# wl_phy_ana_pg_secure register map
Vendor: Texas Instruments
Registers are 32-bit, access per field, reset 0x0 unless marked. A register's access mark holds for its fields unless they carry their own. Offsets are as the file gives them; [hi:lo] are bit positions.

## wl_phy_ana_pg_secure (part 3 of 3)
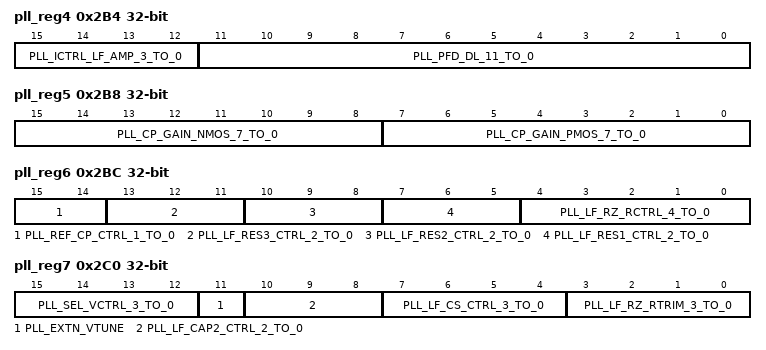
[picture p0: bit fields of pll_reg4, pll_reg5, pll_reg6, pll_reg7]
0x2B4 pll_reg4 — - not used - '0' SW PFD_RESET2; '1' synth_dig dual PFD reset - '0' SW PFD_RESET; '1' synth_dig PFD reset - '0' No UP Delay; '1' extra UP delay based on '00' one pres45 clk delay for UP; '01' - 1.5 pres45 clk delay for UP; '10' 2 pres45 clk delay for UP; '11' - 2.5 pres45 clk delay for UP; - '0' No DN Delay; '1' extra DN delay based on '00' one pres45 clk delay for DN; '01' - 1.5 pres45 clk delay for DN; '10' 2 pres45 clk delay for DN; '11' - 2.5 pres45 clk delay for DN;
  [15:12] PLL_ICTRL_LF_AMP_3_TO_0 rw — Current control for Loop Filter Amp '0000' - No Current '0001' - Max Current (6mA) '0100' - A band current (1.6mA) '0110' - BG band Current (1.2mA) '1111' - Min Current (500uA)
  [11:0] PLL_PFD_DL_11_TO_0 rw — - not used - '0' SW PFD_RESET2; '1' synth_dig dual PFD reset - '0' SW PFD_RESET; '1' synth_dig PFD reset - '0' No UP Delay; '1' extra UP delay based on '00' one pres45 clk delay for UP; '01' - 1.5 pres45 clk delay for UP; '10' 2 pres45 clk delay for UP; '11' - 2.5 pres45 clk delay for UP; - '0' No DN Delay; '1' extra DN delay based on '00' one pres45 clk delay for DN; '01' - 1.5 pres45 clk delay for DN; '10' 2 pres45 clk delay for DN; '11' - 2.5 pres45 clk delay for DN;
0x2B8 pll_reg5 — CP Gain for UP '0x00' - No Current '0x01' - 125uA 0x02 - 62uA 0x04 -125uA 0x08 - 250uA 0x10 - 500uA 0x20 - 1mA 0x40 - 2mA 0x80 - 2mA
  [15:8] PLL_CP_GAIN_NMOS_7_TO_0 rw — CP Gain for DN '0x00' - No Current '0x01' - 125uA 0x02 - 62uA 0x04 -125uA 0x08 - 250uA 0x10 - 500uA 0x20 - 1mA 0x40 - 2mA 0x80 - 2mA
  [7:0] PLL_CP_GAIN_PMOS_7_TO_0 rw — CP Gain for UP '0x00' - No Current '0x01' - 125uA 0x02 - 62uA 0x04 -125uA 0x08 - 250uA 0x10 - 500uA 0x20 - 1mA 0x40 - 2mA 0x80 - 2mA
0x2BC pll_reg6 — Res control for LF Rz 'XX000' 4.5K 'XX001' 5.5K 'XX010' 6.8K 'XX011' 8.8K '011XX' 3K '101XX' 1.5K '111XX' 800
  [15:14] PLL_REF_CP_CTRL_1_TO_0 rw — Res control for Loop filter positive node VCM '00' not connected '01' 6KOhm '10' 4KOhm '11' 6K||4KOhm = 2.4K
  [13:11] PLL_LF_RES3_CTRL_2_TO_0 rw — Res control for LF LPF3 '000' 5.5K '001' 5.5K||8K '010 5.5K || 16K '100' 5.5K|| 32K
  [10:8] PLL_LF_RES2_CTRL_2_TO_0 rw — Res control for LF LPF2 '000' 5.5K '001' 5.5K||8K '010 5.5K || 16K '100' 5.5K|| 32K
  [7:5] PLL_LF_RES1_CTRL_2_TO_0 rw — Res control for LF LPF1 '000' 3.5K '001' 3.5K||5K '010 3.5K || 10K '100' 3.5K|| 20K
  [4:0] PLL_LF_RZ_RCTRL_4_TO_0 rw — Res control for LF Rz 'XX000' 4.5K 'XX001' 5.5K 'XX010' 6.8K 'XX011' 8.8K '011XX' 3K '101XX' 1.5K '111XX' 800
0x2C0 pll_reg7 — RTRIM for RZ over PVT
  [15:12] PLL_SEL_VCTRL_3_TO_0 rw — Control to give VCTRL through R ladder '0000' - 240mV '0001' - 240mV +60mV '1000' - 240mV + 8*60mV '1111' - 1.14V
  [11] PLL_EXTN_VTUNE rw — Enable External Vtune R ladder
  [10:8] PLL_LF_CAP2_CTRL_2_TO_0 rw — Cap control for LF LPF2 '0' - 13pF; '1' - 13pF+6.5pF Cap control for LF LPF3 '0' - 15pF; '1' - 15pF+5.5pF Cap control for LF LPF1 '0' - 5pF; '1' - 5pF+9.5pF
  [7:4] PLL_LF_CS_CTRL_3_TO_0 rw — Cap control for LF CS - not used '000' - 1.5pF '001' -1.5pF + 1.75pF '010' - 1.5pF+3.5pF '100' 1.5pF+7pF
  [3:0] PLL_LF_RZ_RTRIM_3_TO_0 rw — RTRIM for RZ over PVT
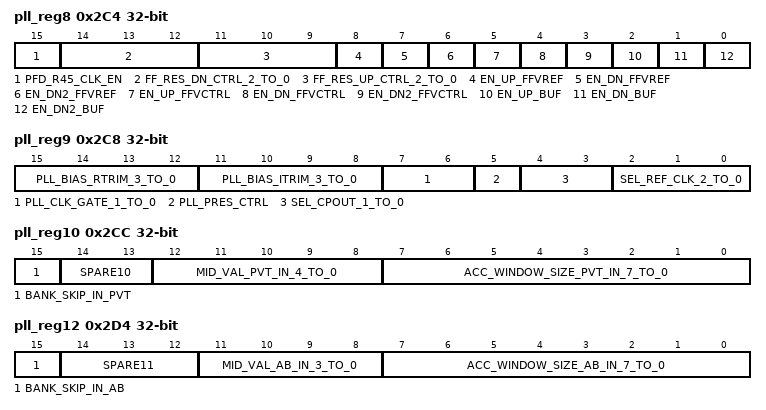
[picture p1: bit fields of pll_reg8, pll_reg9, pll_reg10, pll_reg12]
0x2C4 pll_reg8 — Enable DN2 buffer to FF
  [15] PFD_R45_CLK_EN rw — Enable Pres45 clk to PFD delay Gen block
  [14:12] FF_RES_DN_CTRL_2_TO_0 rw — Res control for FF DN path for both FFVCTRL FFVREF not used '00' - 4KOhm '01' 6KOhm '10' 8KOhm '11' 12KOhm
  [11:9] FF_RES_UP_CTRL_2_TO_0 rw — Res control for FF UP path for both FFVCTRL FFVREF not used '00' - 4KOhm '01' 6KOhm '10' 8KOhm '11' 12KOhm
  [8] EN_UP_FFVREF rw — Enable UP FF to VREF node
  [7] EN_DN_FFVREF rw — Enable DN FF to VREF node
  [6] EN_DN2_FFVREF rw — Enable DN2 FF to VREF node
  [5] EN_UP_FFVCTRL rw — Enable UP FF to VCTRL node
  [4] EN_DN_FFVCTRL rw — Enable DN FF to VCTRL node
  [3] EN_DN2_FFVCTRL rw — Enable DN2 FF to VCTRL node
  [2] EN_UP_BUF rw — Enable UP buffer to FF
  [1] EN_DN_BUF rw — Enable DN buffer to FF
  [0] EN_DN2_BUF rw — Enable DN2 buffer to FF
0x2C8 pll_reg9 — Mux select for DLL CLK to PLL Mux select for XTAL clk to PLL
  [15:12] PLL_BIAS_RTRIM_3_TO_0 rw — Res trim inside V2I amp for amp bias current
  [11:8] PLL_BIAS_ITRIM_3_TO_0 rw — Res trim for V2I Resistor for mirror currents
  [7:6] PLL_CLK_GATE_1_TO_0 rw — Enable DLL CLK out to synth_dig Enable Prescaler clk out to synth_dig
  [5] PLL_PRES_CTRL rw — Control for dummy logic to be kept 0
  [4:3] SEL_CPOUT_1_TO_0 rw — Mux select for DLL VCTRL and PLL VCTRL to test mode '01' - PLL VCTRL to test mode '10' - DLL VCTRL to test mode
  [2:0] SEL_REF_CLK_2_TO_0 rw — Mux select for DLL CLK to PLL Mux select for XTAL clk to PLL
0x2CC pll_reg10 — Number of FREFs over which the FCW should be integrated for error computation for PVT tuning
  [15] BANK_SKIP_IN_PVT rw — Set this bit to skip PVT bank during tuning. The Mid value configured will apply as the PVT Code
  [14:13] SPARE10 rw — SPARE
  [12:8] MID_VAL_PVT_IN_4_TO_0 rw — PVT Mid value. This is the value at which the synth will start for PVT code for convergence
  [7:0] ACC_WINDOW_SIZE_PVT_IN_7_TO_0 rw — Number of FREFs over which the FCW should be integrated for error computation for PVT tuning
0x2D0 pll_reg11 — Beta value for PVT Bank Tuning
  [15:0] BETA_PVT_IN_15_TO_0 rw
0x2D4 pll_reg12 — Number of FREFs over which the FCW should be integrated for error computation for AB tuning
  [15] BANK_SKIP_IN_AB rw — Set this bit to skip AB bank during tuning. The Mid value configured will apply as the AB Code
  [14:12] SPARE11 rw — SPARE
  [11:8] MID_VAL_AB_IN_3_TO_0 rw — AB Mid value. This is the value at which the synth will start for AB code for convergence
  [7:0] ACC_WINDOW_SIZE_AB_IN_7_TO_0 rw — Number of FREFs over which the FCW should be integrated for error computation for AB tuning
0x2D8 pll_reg13 — Beta value for AB Bank Tuning
  [15:0] BETA_AB_IN_15_TO_0 rw
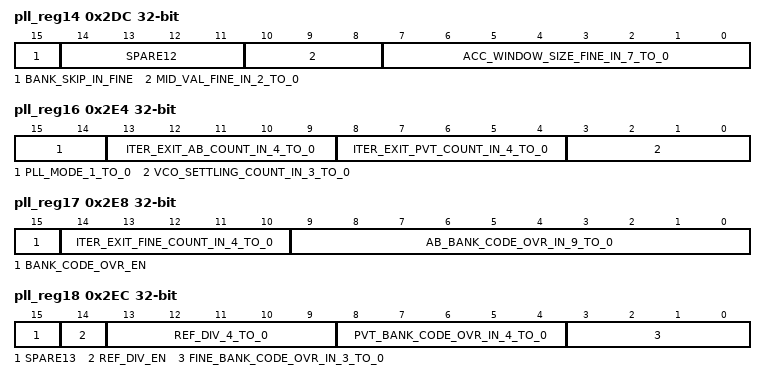
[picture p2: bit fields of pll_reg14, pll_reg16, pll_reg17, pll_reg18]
0x2DC pll_reg14 — Number of FREFs over which the FCW should be integrated for error computation for FINE tuning
  [15] BANK_SKIP_IN_FINE rw — Set this bit to skip FINE bank during tuning. The Mid value configured will apply as the FINE Code
  [14:11] SPARE12 rw — SPARE
  [10:8] MID_VAL_FINE_IN_2_TO_0 rw — FINE Mid value. This is the value at which the synth will start for FINE code for convergence
  [7:0] ACC_WINDOW_SIZE_FINE_IN_7_TO_0 rw — Number of FREFs over which the FCW should be integrated for error computation for FINE tuning
0x2E0 pll_reg15 — Beta value for FINE Bank Tuning
  [15:0] BETA_FINE_IN_15_TO_0 rw
0x2E4 pll_reg16 — Number of FREF clocks to wait for VCO to settle after every bank code update till error accumulation count starts
  [15:14] PLL_MODE_1_TO_0 rw — Defines if the PLL should work in Auto Mode or Stepping Mode 00_ Full auto mode for Bank switching as well as on every iteration within the bank tuning 01_ Iteration stepping is auto_ but Bank switching is Manual. After every bank tuning_ interrupt is generated and tuning is paused. Next bank tuning resumes on synth_kickoff retrigger 10_ Bank switching is auto_ but Iteration stepping is Manual. After every iteration_ interrupt is generated and tuning is paused and resumes on iteration_single_step_in trigger 11_ Both Bank switching and Iteration stepping are manual. Interrupt is generated on every iteration step as well as bank switch and resume on iteration_single_step_in and synth_kickoff triggers respectively
  [13:9] ITER_EXIT_AB_COUNT_IN_4_TO_0 rw — Number of counts after which the iterations for AB bank should stop and signal end of tuning for AB bank for bank switching to FINE
  [8:4] ITER_EXIT_PVT_COUNT_IN_4_TO_0 rw — Number of counts after which the iterations for PVT bank should stop and signal end of tuning for PVT bank for bank switching to AB
  [3:0] VCO_SETTLING_COUNT_IN_3_TO_0 rw — Number of FREF clocks to wait for VCO to settle after every bank code update till error accumulation count starts
0x2E8 pll_reg17 — Override value for the AB Bank code to be used if bank_code_ovr_en is set
  [15] BANK_CODE_OVR_EN rw — Override computed bank code values Set this bit to use override bank code values instead of what is computed every iteration. Can be used for debug mode or FW workarounds
  [14:10] ITER_EXIT_FINE_COUNT_IN_4_TO_0 rw — Number of counts after which the iterations for FINE bank should stop and signal end of tuning for FINE bank for signalling end of tune indication
  [9:0] AB_BANK_CODE_OVR_IN_9_TO_0 rw — Override value for the AB Bank code to be used if bank_code_ovr_en is set
0x2EC pll_reg18 — Override value for the FINE Bank code to be used if bank_code_ovr_en is set
  [15] SPARE13 rw — SPARE
  [14] REF_DIV_EN rw — Enable REF CLK division for FLL counter_ internal FSM works on REF CLK
  [13:9] REF_DIV_4_TO_0 rw — REF CLK division factor for FLL
  [8:4] PVT_BANK_CODE_OVR_IN_4_TO_0 rw — Override value for the PVT Bank code to be used if bank_code_ovr_en is set
  [3:0] FINE_BANK_CODE_OVR_IN_3_TO_0 rw — Override value for the FINE Bank code to be used if bank_code_ovr_en is set
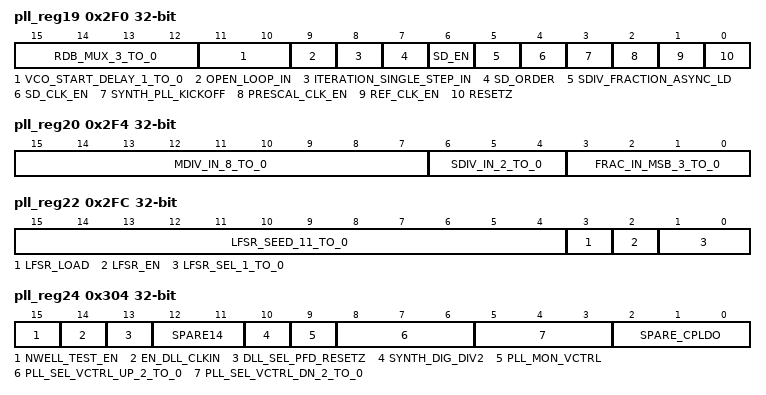
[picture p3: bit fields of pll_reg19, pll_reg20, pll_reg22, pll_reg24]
0x2F0 pll_reg19 — RESETZ
  [15:12] RDB_MUX_3_TO_0 rw — rdb_mux Read back controls 0x6 = PLLOUT_REG2 = fcw_counter_expected 0x5 = PLLOUT_REG2 = fcw_counter 0x4 = PLLOUT_REG2 = fcw_error 0x3 = PLLOUT_REG2 = fcw_error_acc 0x2 = PLLOUT_REG2 = beta_scale_selected_val 0x1 = PLLOUT_REG2 = bank_code_err; bank_code_iter_final 0x0 = PLLOUT_REG2 = fine_bank_code_apply ab_bank_code_apply
  [11:10] VCO_START_DELAY_1_TO_0 rw — controls the delay between _synth_pll_kickoff_ and delayed pll_kickoff(when the mid coded gets apllied to the VCO) 00 _64 clock cycles of ref_clk 01_128 clock cycles of ref_clk 10_16 clock cycles of ref_clk 11 _32 clock cycles of ref_clk
  [9] OPEN_LOOP_IN rw — Not used
  [8] ITERATION_SINGLE_STEP_IN rw
  [7] SD_ORDER rw
  [6] SD_EN rw — Enable SDM
  [5] SDIV_FRACTION_ASYNC_LD rw — A toggle of this signal loads new SDIV and Fraction after digital tune_ must be stable at least two sdm clock cycles. Added for Osprey support of PLL Reloc
  [4] SD_CLK_EN rw — Enable SDM CLK
  [3] SYNTH_PLL_KICKOFF rw — Enable Digital VCO cap tuning
  [2] PRESCAL_CLK_EN rw — Enable Prescaler CLK
  [1] REF_CLK_EN rw — Enable Reference CLK
  [0] RESETZ rw
0x2F4 pll_reg20 — MSB part of fractional input
  [15:7] MDIV_IN_8_TO_0 rw — Current mdiv_in allocation of 9 bits
  [6:4] SDIV_IN_2_TO_0 rw — Current sdiv_in allocation of 3 bits
  [3:0] FRAC_IN_MSB_3_TO_0 rw — MSB part of fractional input
0x2F8 pll_reg21 — LSB part of fractional input
  [15:0] FRAC_IN_LSB_15_TO_0 rw
0x2FC pll_reg22
  [15:4] LFSR_SEED_11_TO_0 rw — seed value for lfsr to dither the LSB
  [3] LFSR_LOAD rw — Load the lfsr seed to Lfsr register
  [2] LFSR_EN rw — enable lfsr to dither frac LSB
  [1:0] LFSR_SEL_1_TO_0 rw — 00 _ [15] ^[14] ^[12]^[3] 01 _ [15]^[12]^[8]^[5] 10 _[15]^[14]^[13]^[12]^[11]^[0] 11 _ [15]
0x300 pll_reg23 — acc1 seed value to be loaded initially default is 0
  [15:0] SDM_ACC1_SEED_15_TO_0 rw
0x304 pll_reg24 — Spare
  [15] NWELL_TEST_EN rw — Enable NWELL testmode
  [14] EN_DLL_CLKIN rw — Enable input clock to DLL
  [13] DLL_SEL_PFD_RESETZ rw — Mux Select for DLL RESETZ in DLL PFD
  [12:11] SPARE14 rw — SPARE
  [10] SYNTH_DIG_DIV2 rw — Enable DIV2 for Pres clk to synth dig
  [9] PLL_MON_VCTRL rw — Enable Monitoring of VCTRL to detect PLL out of lock
  [8:6] PLL_SEL_VCTRL_UP_2_TO_0 rw — Select high voltage limit for VCTRL to detect PLL out of lock '111' - 1.23V every step is 70mV decrease
  [5:3] PLL_SEL_VCTRL_DN_2_TO_0 rw — Select low voltage limit for VCTRL to detect PLL out of lock '000' - 185mV every step is 70mV increase
  [2:0] SPARE_CPLDO rw — Spare
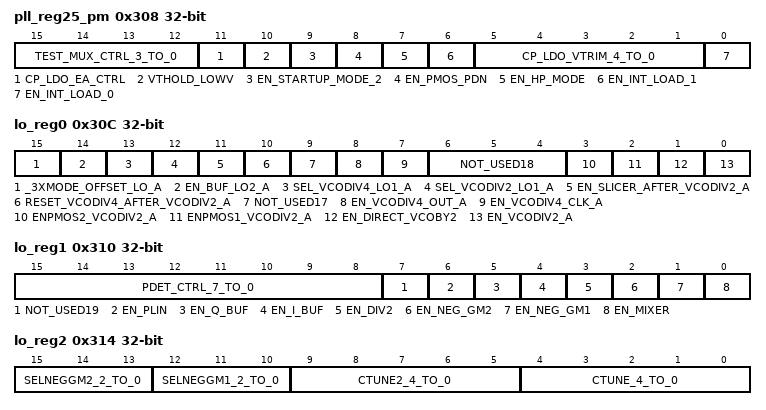
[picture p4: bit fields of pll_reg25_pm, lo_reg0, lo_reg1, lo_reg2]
0x308 pll_reg25_pm — EN_INTLOAD Enable internal load. Making any bit ?H? enables 50% of the internal load ?L_L? = 0mA ?L_H? = 3.5mA (across PVT_ 1.4mA ? 6mA) ?H_L? = 3.5mA (across PVT_ 1.4mA ? 6mA) ?H_H? = 7mA (across PVT_ 2.8mA ? 11mA)
  [15:12] TEST_MUX_CTRL_3_TO_0 rw — TEST MUX Control 'H' bring out Vout_2 'H' Enable Tmux
  [11] CP_LDO_EA_CTRL rw — Used in EA block?s start-up amp ?L? = Short out 20k degen of current source which pumps current into EA cap ?H? = Enable the 20k degen of current source which pumps current into EA cap
  [10] VTHOLD_LOWV rw — Start-up bit for CPLDO. Enables extra current through EA ?H? = disable extra current(slow start)_ ?L? = fast-start
  [9] EN_STARTUP_MODE_2 rw — EN_STARTUPMODE_2 Enable fast start mode 2 (This is a static bit_ It doesn?t need to toggle) ?H? = burn 10uA extra current in error amp ?L? = burn only 2.5uA extra current in error amp
  [8] EN_PMOS_PDN rw — EN_PMOSPDN Enable pull down path in buffer to reduce overshoots in Vout ?L? = Enable PD_ ?H? = Disable PD
  [7] EN_HP_MODE rw — EN_HPMODE Enable High Power mode_ i.e. _ burn extra tail current in buffer ?H? = Enable HPmode_ ?L?= Disable Hpmode
  [6] EN_INT_LOAD_1 rw — EN_INTLOAD Enable internal load. Making any bit ?H? enables 50% of the internal load ?L_L? = 0mA ?L_H? = 3.5mA (across PVT_ 1.4mA ? 6mA) ?H_L? = 3.5mA (across PVT_ 1.4mA ? 6mA) ?H_H? = 7mA (across PVT_ 2.8mA ? 11mA)
  [5:1] CP_LDO_VTRIM_4_TO_0 rw — VOUT_TRIM LDO trim LSB approximately 20mV
  [0] EN_INT_LOAD_0 rw — EN_INTLOAD Enable internal load. Making any bit ?H? enables 50% of the internal load ?L_L? = 0mA ?L_H? = 3.5mA (across PVT_ 1.4mA ? 6mA) ?H_L? = 3.5mA (across PVT_ 1.4mA ? 6mA) ?H_H? = 7mA (across PVT_ 2.8mA ? 11mA)
0x30C lo_reg0 — Enable A band VCODIV2
  [15] _3XMODE_OFFSET_LO_A rw — Configures the A band output LO2 (2nd input to OFFSET LO MIXER) to high enabling 3x mode of OFFSET MIXER
  [14] EN_BUF_LO2_A rw — Enables buffer which sends VCO A band as LO2 input to OFFSET LO MIXER
  [13] SEL_VCODIV4_LO1_A rw — Selects VCO_4 signal as LO1 input to OFFSET LO MIXER
  [12] SEL_VCODIV2_LO1_A rw — Selects VCO_2 signal as LO1 input to OFFSET LO MIXER
  [11] EN_SLICER_AFTER_VCODIV2_A rw — Enable buffer after A band VCODIV2 module
  [10] RESET_VCODIV4_AFTER_VCODIV2_A rw — Reset IVCODIV4 after A band VCODIV2
  [9] NOT_USED17 rw — Not used
  [8] EN_VCODIV4_OUT_A rw — Enable output of VCODIV4 divider sitting after VCODIV2 divider in A band VCODIV block
  [7] EN_VCODIV4_CLK_A rw — Enable clock of VCODIV4 divider sitting after VCODIV2 divider in A band VCODIV block
  [6:4] NOT_USED18 rw — Not used
  [3] ENPMOS2_VCODIV2_A rw — Enable 2X extra drive for PMOS in A band VCODIV2
  [2] ENPMOS1_VCODIV2_A rw — Enable 1X extra drive for PMOS in A band VCODIV2
  [1] EN_DIRECT_VCOBY2 rw — Enable the path of VCO_2 muxed at final buffer of offset-LO drivers to enable 3x(VCO_2) mode
  [0] EN_VCODIV2_A rw — Enable A band VCODIV2
0x310 lo_reg1 — Enable of offset LO mixer
  [15:8] PDET_CTRL_7_TO_0 rw — PDET configuration
  [7] NOT_USED19 rw — Not used
  [6] EN_PLIN rw — Controls the step size of bias generation in div2
  [5] EN_Q_BUF rw — Enable of Q path buffers after div2
  [4] EN_I_BUF rw — Enable of I path buffers after div2
  [3] EN_DIV2 rw — Enable of div2 mixer
  [2] EN_NEG_GM2 rw — Enable of negative gm load at 2nd stage output
  [1] EN_NEG_GM1 rw — Enable of negative gm load at 1st stage output
  [0] EN_MIXER rw — Enable of offset LO mixer
0x314 lo_reg2 — cap trim for 1st stage capacitor bank
  [15:13] SELNEGGM2_2_TO_0 rw — Bias generation for negative gm at 2nd stage
  [12:10] SELNEGGM1_2_TO_0 rw — Bias generation for negative gm at 1st stage
  [9:5] CTUNE2_4_TO_0 rw — cap trim for 2nd stage capacitor bank
  [4:0] CTUNE_4_TO_0 rw — cap trim for 1st stage capacitor bank
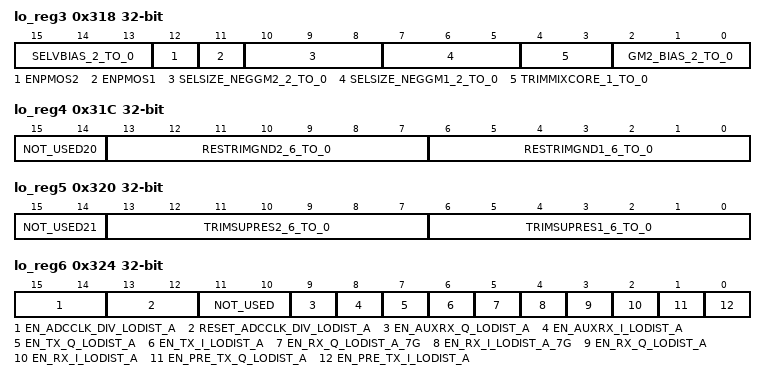
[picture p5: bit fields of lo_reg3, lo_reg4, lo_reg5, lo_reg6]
0x318 lo_reg3 — Bias generation for 2nd stage amplifier
  [15:13] SELVBIAS_2_TO_0 rw — Bias generation for div2 block
  [12] ENPMOS2 rw — Enable 2x PMOS arm in parallel to div2 default load
  [11] ENPMOS1 rw — Enable 1x PMOS arm in parallel to div2 default load
  [10:8] SELSIZE_NEGGM2_2_TO_0 rw — Selecting arms of negative-gm at 2nd stage (8x_4x_2x)
  [7:5] SELSIZE_NEGGM1_2_TO_0 rw — Selecting arms of negative-gm at 1st stage (8x_4x_2x)
  [4:3] TRIMMIXCORE_1_TO_0 rw — Not used
  [2:0] GM2_BIAS_2_TO_0 rw — Bias generation for 2nd stage amplifier
0x31C lo_reg4 — Trim control for resistor on ground side of 1st stage
  [15:14] NOT_USED20 rw — Not used
  [13:7] RESTRIMGND2_6_TO_0 rw — Trim control for resistor on ground side of 2nd stage
  [6:0] RESTRIMGND1_6_TO_0 rw — Trim control for resistor on ground side of 1st stage
0x320 lo_reg5 — Trim control for resistor on supply side of 1st stage
  [15:14] NOT_USED21 rw — Not used
  [13:7] TRIMSUPRES2_6_TO_0 rw — Trim control for resistor on supply side of 2nd stage
  [6:0] TRIMSUPRES1_6_TO_0 rw — Trim control for resistor on supply side of 1st stage
0x324 lo_reg6 — Enables for A band buffers preceding TX clock buffers_ I phase
  [15:14] EN_ADCCLK_DIV_LODIST_A rw — Bits to divide the ADC CLK by 4 in A band LO DIST. Required setting = 11. Bit 15 for DIV 1 and 14 for Div 2
  [13:12] RESET_ADCCLK_DIV_LODIST_A rw — Reset ADC CLK divider. Required setting = 11 to reset the divider.
  [11:10] NOT_USED rw
  [9] EN_AUXRX_Q_LODIST_A rw — Enables for A band AUXRX clock buffers_ Q phase
  [8] EN_AUXRX_I_LODIST_A rw — Enables for A band AUXRX clock buffers_ I phase
  [7] EN_TX_Q_LODIST_A rw — Enables for A band TX clock buffers_ Q phase
  [6] EN_TX_I_LODIST_A rw — Enables for A band TX clock buffers_ I phase
  [5] EN_RX_Q_LODIST_A_7G rw — Enables for A (7G) band RX clock buffers_ Q phase
  [4] EN_RX_I_LODIST_A_7G rw — Enables for A (7G) band RX clock buffers _I phase
  [3] EN_RX_Q_LODIST_A rw — Enables for A band RX clock buffers_ Q phase
  [2] EN_RX_I_LODIST_A rw — Enables for A band RX clock buffers _I phase
  [1] EN_PRE_TX_Q_LODIST_A rw — Enables for A band buffers preceding TX clock buffers_ Q phase
  [0] EN_PRE_TX_I_LODIST_A rw — Enables for A band buffers preceding TX clock buffers_ I phase
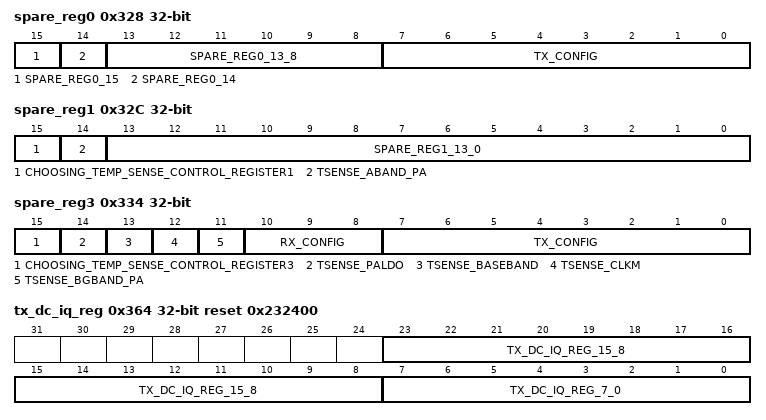
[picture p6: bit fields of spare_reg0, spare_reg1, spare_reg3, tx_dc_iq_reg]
0x328 spare_reg0 reset not defined — Reserved for Tx config (a-band)
  [15] SPARE_REG0_15 rw — Not used
  [14] SPARE_REG0_14 rw — Not used
  [13:8] SPARE_REG0_13_8 rw — Not used
  [7:0] TX_CONFIG rw — Reserved for Tx config (a-band)
0x32C spare_reg1 reset not defined — Not used
  [15] CHOOSING_TEMP_SENSE_CONTROL_REGISTER1 rw — 0- choose internal spare register 1- choose controls coming from ADC controller
  [14] TSENSE_ABAND_PA rw — Temp sensor close to a-band PA
  [13:0] SPARE_REG1_13_0 rw — Not used
0x330 spare_reg2 reset 0x80008 — Not used
  [15:0] SPARE_REG2_15_0 rw
0x334 spare_reg3 reset not defined — Reserved for Tx config
  [15] CHOOSING_TEMP_SENSE_CONTROL_REGISTER3 rw — 0- choose internal spare registers 1- choose controls coming from ADC controller
  [14] TSENSE_PALDO rw — Temp sensor close to PA LDO
  [13] TSENSE_BASEBAND rw — Temp sensor close to baseband section
  [12] TSENSE_CLKM rw — Temp sensor close to VCO_CLKM module
  [11] TSENSE_BGBAND_PA rw — Temp sensor close to bg-band PA
  [10:8] RX_CONFIG rw — Reserved for Rx config (bg-band)
  [7:0] TX_CONFIG rw — Reserved for Tx config
0x338 spare_reg4 reset 0x100010 — Not used
  [15:0] SPARE_REG4_15_0 rw
0x33C spare_reg5 reset 0x110011 — Not used
  [15:0] SPARE_REG5_15_0 rw
0x340 spare_reg6 reset 0x120012 — Not used
  [15:0] SPARE_REG6_15_0 rw
0x344 spare_reg7 reset 0x130013 — Not used
  [15:0] SPARE_REG7_15_0 rw
0x348 spare_reg8 reset 0x140014 — Not used
  [15:0] SPARE_REG8_15_0 rw
0x34C spare_reg9 reset 0x150015 — Not used
  [15:0] SPARE_REG9_15_0 rw
0x350 spare_reg10 reset 0x160016 — Not used
  [15:0] SPARE_REG10_15_0 rw
0x354 spare_reg11 reset 0x170017 — Not used
  [15:0] SPARE_REG11_15_0 rw
0x358 spare_reg12 reset 0x180018 — Not used
  [15:0] SPARE_REG12_15_0 rw
0x35C spare_reg13 reset 0x190019 — Not used
  [15:0] SPARE_REG13_15_0 rw
0x360 spare_reg14 reset 0x1A001A — Not used
  [15:0] SPARE_REG14_15_0 rw
0x364 tx_dc_iq_reg reset 0x232400 (reset mask 0xFFFF00) — MEM_TXDCI
  [23:8] TX_DC_IQ_REG_15_8 rw — MEM_TXDCQ
  [7:0] TX_DC_IQ_REG_7_0 rw — MEM_TXDCI
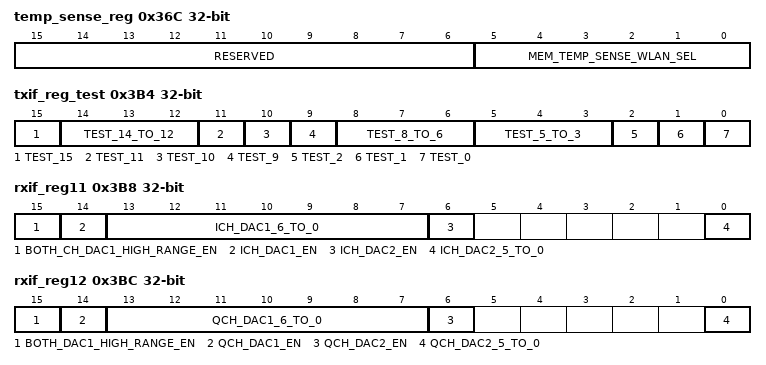
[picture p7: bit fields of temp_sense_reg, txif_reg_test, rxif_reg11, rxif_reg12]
0x36C temp_sense_reg
  [15:6] RESERVED rw, [5:0] MEM_TEMP_SENSE_WLAN_SEL rw
0x370 pllout_reg0 reset 0x250025
  [15:0] PLLOUT_REG0_15_0 rw
0x374 pllout_reg1 reset 0x260026
  [15:0] PLLOUT_REG1_15_0 rw
0x378 pllout_reg2 reset 0x270027
  [15:0] PLLOUT_REG2_15_0 rw
0x37C pllout_reg3 reset 0x280028
  [15:0] PLLOUT_REG3_15_0 rw
0x380 pllout_reg4 reset 0x290029
  [15:0] PLLOUT_REG4_15_0 rw
0x384 pllout_reg5 reset 0x2A002A
  [15:0] PLLOUT_REG5_15_0 rw
0x388 pllout_reg6 reset 0x2B002B
  [15:0] PLLOUT_REG6_15_0 rw
0x38C pllout_reg7 reset 0x2C002C
  [15:0] PLLOUT_REG7_15_0 rw
0x390 spareout_reg0 reset 0x2D002D
  [15:0] SPAREOUT_REG0_15_0 rw
0x394 spareout_reg1 reset 0x2E002E
  [15:0] SPAREOUT_REG1_15_0 rw
0x398 spareout_reg2 reset 0x2F002F
  [15:0] SPAREOUT_REG2_15_0 rw
0x39C spareout_reg3 reset 0x300030
  [15:0] SPAREOUT_REG3_15_0 rw
0x3A8 txfea_reg6 reset 0x310031 — MEM_TXFEA_REG6
  [15:0] TXFEA_REG6_15_0 rw
0x3AC txfea_reg7 reset 0x320032 — MEM_TXFEA_REG7
  [15:0] TXFEA_REG7_15_0 rw
0x3B0 txfea_reg8 reset 0x330033 — MEM_TXFEA_REG8
  [15:0] TXFEA_REG8_15_0 rw
0x3B4 txif_reg_test — Enable VCM QCH AMP in To TP
  [15] TEST_15 rw — 000=Disable ICH FILT o_p 110= ICH FILT o_p to TEST 101= ICH FILT o_p to LOOPBACK 011= ICH FILT o_p to Res -LOOPBACK
  [14:12] TEST_14_TO_12 rw — 000=Disable ICH AMP o_p 110= ICH AMP o_p to TEST 101= ICH AMP o_p to LOOPBACK 011= ICH AMP o_p to Res -LOOPBACK
  [11] TEST_11 rw — Enable ICH DAC o_p to test pin
  [10] TEST_10 rw — Enable VCM ICH Mixer to TP
  [9] TEST_9 rw — Enable VCM ICH AMP in To TP
  [8:6] TEST_8_TO_6 rw — 000=Disable QCH FILT o_p 110= QCH FILT o_p to TEST 101= QCH FILT o_p to LOOPBACK 011= QCH FILT o_p to Res -LOOPBACK
  [5:3] TEST_5_TO_3 rw — 000=Disable QCH AMP o_p 110= QCH AMP o_p to TEST 101= QCH AMP o_p to LOOPBACK 011= QCH AMP o_p to Res -LOOPBACK
  [2] TEST_2 rw — Enable QCH DAC o_p to test pin
  [1] TEST_1 rw — Enable VCM QCH Mixer to TP
  [0] TEST_0 rw — Enable VCM QCH AMP in To TP
0x3B8 rxif_reg11 — DAC 2 code (MSB is Sign BIT)
  [15] BOTH_CH_DAC1_HIGH_RANGE_EN rw — DAC 1 High Offset Mode (Aband) 0= Resolution=20mV 1= Resolution=40mV
  [14] ICH_DAC1_EN rw — DAC 1 Enable
  [13:7] ICH_DAC1_6_TO_0 rw — DAC 1 code (MSB is Sign BIT)
  [6] ICH_DAC2_EN rw — DAC 2 En
  [0] ICH_DAC2_5_TO_0 rw — DAC 2 code (MSB is Sign BIT)
0x3BC rxif_reg12 — DAC 2 code (MSB is Sign BIT)
  [15] BOTH_DAC1_HIGH_RANGE_EN rw — DAC 2 High Offset Mode (Aband) 0= Resolution=5mV 1= Resolution=10mV
  [14] QCH_DAC1_EN rw — DAC 1 Enable
  [13:7] QCH_DAC1_6_TO_0 rw — DAC 1 code (MSB is Sign BIT)
  [6] QCH_DAC2_EN rw — DAC 2 En
  [0] QCH_DAC2_5_TO_0 rw — DAC 2 code (MSB is Sign BIT)
0x3C0 wlan_pm_reg10 reset 0x1C001C — MEM_WLAN_PM_REG10
  [15:0] WLAN_PM_REG10_15_1 rw
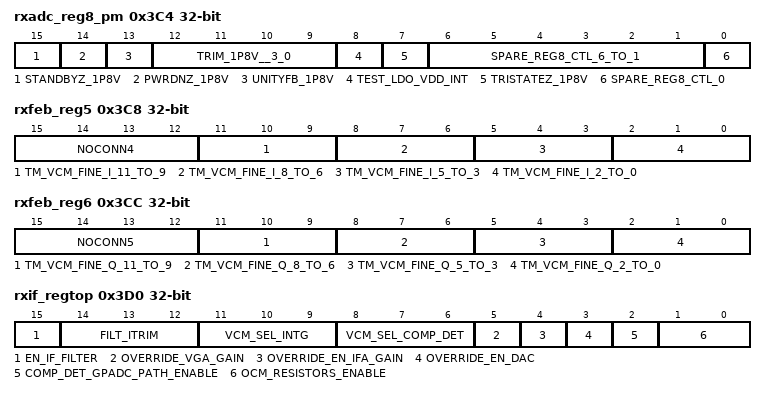
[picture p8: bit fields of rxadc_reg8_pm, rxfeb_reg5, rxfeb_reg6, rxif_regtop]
0x3C4 rxadc_reg8_pm — TEST_I_FB_5U
  [15] STANDBYZ_1P8V rw
  [14] PWRDNZ_1P8V rw
  [13] UNITYFB_1P8V rw
  [12:9] TRIM_1P8V__3_0 rw — TRIM_1P8V
  [8] TEST_LDO_VDD_INT rw
  [7] TRISTATEZ_1P8V rw
  [6:1] SPARE_REG8_CTL_6_TO_1 rw
  [0] SPARE_REG8_CTL_0 rw — TEST_I_FB_5U
0x3C8 rxfeb_reg5 — Trim control for PMIX Ich connected to LOM and IFM. Coarse Trim decides the tap point. This is Fine Trim. 100-Mid code 011 - 10mV Lower 101- 10mV higher
  [15:12] NOCONN4 rw — Not connected
  [11:9] TM_VCM_FINE_I_11_TO_9 rw — Trim control for PMIX Ich connected to LOP and IFP. Coarse Trim decides the tap point. This is Fine Trim. 100-Mid code 011 - 10mV Lower 101- 10mV higher
  [8:6] TM_VCM_FINE_I_8_TO_6 rw — Trim control for PMIX Ich connected to LOP and IFM. Coarse Trim decides the tap point.This is Fine Trim. 100-Mid code 011 - 10mV Lower 101- 10mV higher
  [5:3] TM_VCM_FINE_I_5_TO_3 rw — Trim control for PMIX Ich connected to LOM and IFP. Coarse Trim decides the tap point. This is Fine Trim. 100-Mid code 011 - 10mV Lower 101- 10mV higher
  [2:0] TM_VCM_FINE_I_2_TO_0 rw — Trim control for PMIX Ich connected to LOM and IFM. Coarse Trim decides the tap point. This is Fine Trim. 100-Mid code 011 - 10mV Lower 101- 10mV higher
0x3CC rxfeb_reg6 — Trim control for PMIX Qch connected to LOM and IFM. Coarse Trim decides the tap point. This is Fine Trim. 100-Mid code 011 - 10mV Lower 101- 10mV higher
  [15:12] NOCONN5 rw — Not connected
  [11:9] TM_VCM_FINE_Q_11_TO_9 rw — Trim control for PMIX Qch connected to LOP and IFP. Coarse Trim decides the tap point. This is Fine Trim. 100-Mid code 011 - 10mV Lower 101- 10mV higher
  [8:6] TM_VCM_FINE_Q_8_TO_6 rw — Trim control for PMIX Qch connected to LOP and IFM. Coarse Trim decides the tap point.This is Fine Trim. 100-Mid code 011 - 10mV Lower 101- 10mV higher
  [5:3] TM_VCM_FINE_Q_5_TO_3 rw — Trim control for PMIX Qch connected to LOM and IFP. Coarse Trim decides the tap point. This is Fine Trim. 100-Mid code 011 - 10mV Lower 101- 10mV higher
  [2:0] TM_VCM_FINE_Q_2_TO_0 rw — Trim control for PMIX Qch connected to LOM and IFM. Coarse Trim decides the tap point. This is Fine Trim. 100-Mid code 011 - 10mV Lower 101- 10mV higher
0x3D0 rxif_regtop — Enable OCM resistors 0=width=1.5um 1=width=2um
  [15] EN_IF_FILTER rw — Enable filter
  [14:12] FILT_ITRIM rw — Top level trim
  [11:9] VCM_SEL_INTG rw — VCM INTG 000=440mV 001=470mV 010=500mV nom ... 111=650mV
  [8:6] VCM_SEL_COMP_DET rw — VCM ComDET 000=VCM INTG -80mV 001=VCM INTG -100mV? 111=VCM INTG -200mV
  [5] OVERRIDE_VGA_GAIN rw — Mux to select modem_REG for VGA gain
  [4] OVERRIDE_EN_IFA_GAIN rw — Mux to select modem_REG for IFA gain
  [3] OVERRIDE_EN_DAC rw — Mux to select modem_REG for DAC
  [2] COMP_DET_GPADC_PATH_ENABLE rw — COMP DET_O_P to GPADC
  [1:0] OCM_RESISTORS_ENABLE rw — Enable OCM resistors 0=width=1.5um 1=width=2um
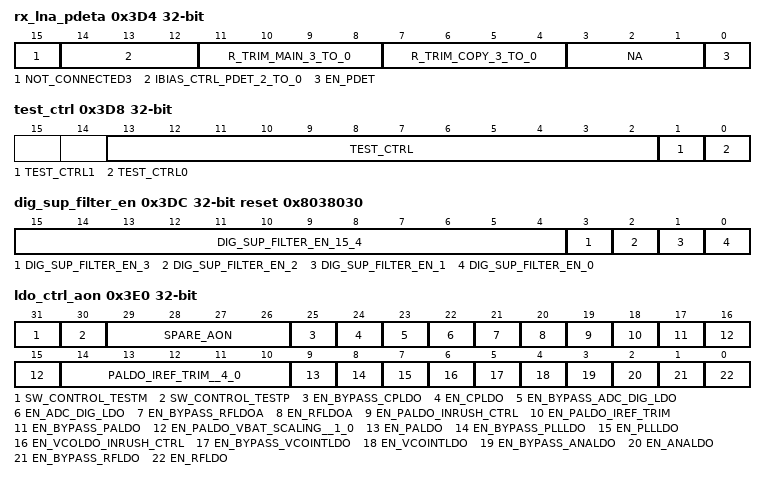
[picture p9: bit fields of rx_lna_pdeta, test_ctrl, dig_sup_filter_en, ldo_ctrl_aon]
0x3D4 rx_lna_pdeta — Enable bit for PDET at LNA Output
  [15] NOT_CONNECTED3 rw — Not Connected
  [14:12] IBIAS_CTRL_PDET_2_TO_0 rw — Ibias control for PDET at LNA Output
  [11:8] R_TRIM_MAIN_3_TO_0 rw — Resistor trim for the Main Branch
  [7:4] R_TRIM_COPY_3_TO_0 rw — Resistor trim for the Replica Branch
  [3:1] NA rw
  [0] EN_PDET rw — Enable bit for PDET at LNA Output
0x3D8 test_ctrl — Control of switch from RFCIO TESTP_VDRAIN of OCP cells to TESTP_PMCIO
  [13:2] TEST_CTRL rw — Not used
  [1] TEST_CTRL1 rw — Control of switch from RFCIO TESTM_VGATE of OCP cells to TESTM_PMCIO
  [0] TEST_CTRL0 rw — Control of switch from RFCIO TESTP_VDRAIN of OCP cells to TESTP_PMCIO
0x3DC dig_sup_filter_en reset 0x8038030 (reset mask 0xFFFFFFF0) — Enable RC filter on VDD_DIG_SW supply in bg band
  [15:4] DIG_SUP_FILTER_EN_15_4 rw — Not used
  [3] DIG_SUP_FILTER_EN_3 rw — Enable RC filter on VDD_DIG_SW supply in a band
  [2] DIG_SUP_FILTER_EN_2 rw — Not used
  [1] DIG_SUP_FILTER_EN_1 rw — Enable RC filter on VDD_DIG supply
  [0] DIG_SUP_FILTER_EN_0 rw — Enable RC filter on VDD_DIG_SW supply in bg band
0x3E0 ldo_ctrl_aon rw — EN_RFLDO
  [31] SW_CONTROL_TESTM — Control of the switch from RFCIO to TESTM
  [30] SW_CONTROL_TESTP — Control of the switch from RFCIO to TESTP
  [29:26] SPARE_AON
  [25] EN_BYPASS_CPLDO
  [24] EN_CPLDO
  [23] EN_BYPASS_ADC_DIG_LDO
  [22] EN_ADC_DIG_LDO
  [21] EN_BYPASS_RFLDOA
  [20] EN_RFLDOA
  [19] EN_PALDO_INRUSH_CTRL
  [18] EN_PALDO_IREF_TRIM
  [17] EN_BYPASS_PALDO
  [16:15] EN_PALDO_VBAT_SCALING__1_0 — EN_PALDO_VBAT_SCALING
  [14:10] PALDO_IREF_TRIM__4_0 — PALDO_IREF_TRIM
  [9] EN_PALDO
  [8] EN_BYPASS_PLLLDO
  [7] EN_PLLLDO
  [6] EN_VCOLDO_INRUSH_CTRL
  [5] EN_BYPASS_VCOINTLDO
  [4] EN_VCOINTLDO
  [3] EN_BYPASS_ANALDO
  [2] EN_ANALDO
  [1] EN_BYPASS_RFLDO
  [0] EN_RFLDO
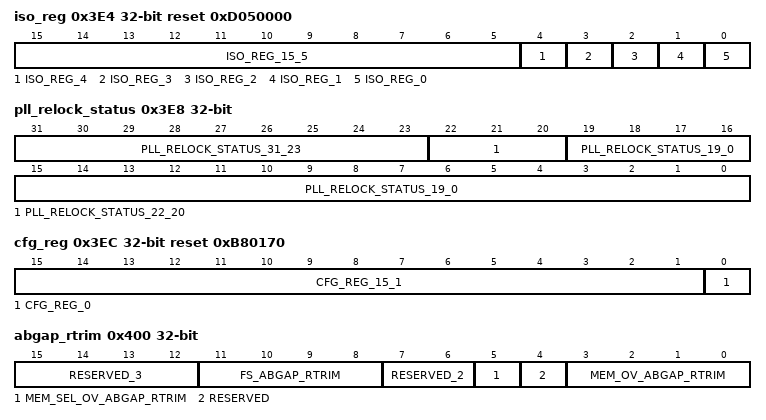
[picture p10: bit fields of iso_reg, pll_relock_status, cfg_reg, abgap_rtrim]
0x3E4 iso_reg reset 0xD050000 (reset mask 0xFFFF0000) — MEM_ISO_ADC
  [15:5] ISO_REG_15_5 rw — Reserve_5_15
  [4] ISO_REG_4 rw — MEM_ISO_PLL_OUT
  [3] ISO_REG_3 rw — MEM_ISO_IF_COMP_DET
  [2] ISO_REG_2 rw — MEM_ISO_HIGH_TEMP_DET
  [1] ISO_REG_1 rw — MEM_ISO_DAC_CLK
  [0] ISO_REG_0 rw — MEM_ISO_ADC
0x3E8 pll_relock_status rw reset not defined — PLL_FRACTIONAL
  [31:23] PLL_RELOCK_STATUS_31_23 — Reserve_23_31
  [22:20] PLL_RELOCK_STATUS_22_20 — PLL_SDIV
  [19:0] PLL_RELOCK_STATUS_19_0 — PLL_FRACTIONAL
0x3EC cfg_reg reset 0xB80170 (reset mask 0xFFFFFFFE) — 0 - use HW (Dynamic) configuration 1 - use Ana-Reg MMR (Static ) configuration Exaple for dynamic configuration are Tx Cfg outptu (Tx Filter_ Mixer_ PPA _ PA_ AUXRX)
  [15:1] CFG_REG_15_1 rw — CFG_REG_15_2
  [0] CFG_REG_0 rw — 0 - use HW (Dynamic) configuration 1 - use Ana-Reg MMR (Static ) configuration Exaple for dynamic configuration are Tx Cfg outptu (Tx Filter_ Mixer_ PPA _ PA_ AUXRX)
0x400 abgap_rtrim
  [15:12] RESERVED_3 rw, [11:8] FS_ABGAP_RTRIM rw, [7:6] RESERVED_2 rw, [5] MEM_SEL_OV_ABGAP_RTRIM rw, [4] RESERVED rw, [3:0] MEM_OV_ABGAP_RTRIM rw
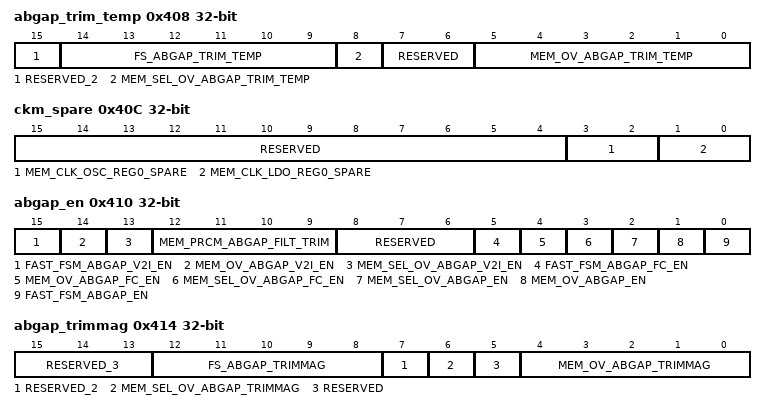
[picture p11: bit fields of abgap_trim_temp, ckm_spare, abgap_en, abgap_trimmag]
0x408 abgap_trim_temp
  [15] RESERVED_2 rw, [14:9] FS_ABGAP_TRIM_TEMP rw, [8] MEM_SEL_OV_ABGAP_TRIM_TEMP rw, [7:6] RESERVED rw, [5:0] MEM_OV_ABGAP_TRIM_TEMP rw
0x40C ckm_spare
  [15:4] RESERVED rw, [3:2] MEM_CLK_OSC_REG0_SPARE rw, [1:0] MEM_CLK_LDO_REG0_SPARE rw
0x410 abgap_en
  [15] FAST_FSM_ABGAP_V2I_EN rw, [14] MEM_OV_ABGAP_V2I_EN rw, [13] MEM_SEL_OV_ABGAP_V2I_EN rw, [12:9] MEM_PRCM_ABGAP_FILT_TRIM rw, [8:6] RESERVED rw, [5] FAST_FSM_ABGAP_FC_EN rw, [4] MEM_OV_ABGAP_FC_EN rw, [3] MEM_SEL_OV_ABGAP_FC_EN rw, [2] MEM_SEL_OV_ABGAP_EN rw, [1] MEM_OV_ABGAP_EN rw, [0] FAST_FSM_ABGAP_EN rw
0x414 abgap_trimmag
  [15:13] RESERVED_3 rw, [12:8] FS_ABGAP_TRIMMAG rw, [7] RESERVED_2 rw, [6] MEM_SEL_OV_ABGAP_TRIMMAG rw, [5] RESERVED rw, [4:0] MEM_OV_ABGAP_TRIMMAG rw
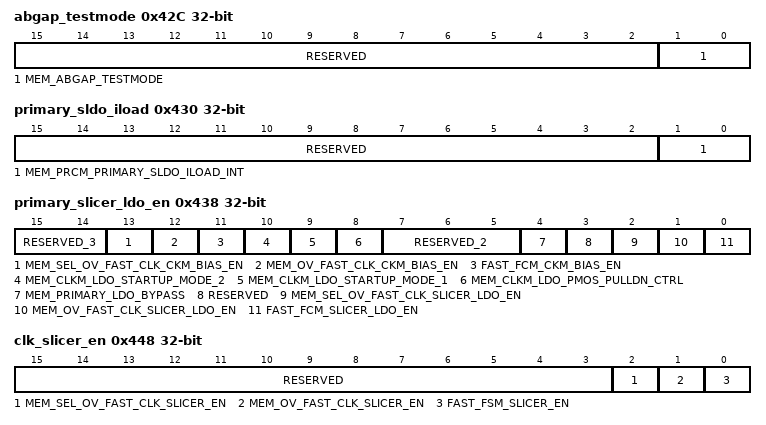
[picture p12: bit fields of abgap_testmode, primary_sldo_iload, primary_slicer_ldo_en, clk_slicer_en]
0x42C abgap_testmode
  [15:2] RESERVED rw, [1:0] MEM_ABGAP_TESTMODE rw
0x430 primary_sldo_iload
  [15:2] RESERVED rw, [1:0] MEM_PRCM_PRIMARY_SLDO_ILOAD_INT rw
0x438 primary_slicer_ldo_en
  [15:14] RESERVED_3 rw, [13] MEM_SEL_OV_FAST_CLK_CKM_BIAS_EN rw, [12] MEM_OV_FAST_CLK_CKM_BIAS_EN rw, [11] FAST_FCM_CKM_BIAS_EN rw, [10] MEM_CLKM_LDO_STARTUP_MODE_2 rw, [9] MEM_CLKM_LDO_STARTUP_MODE_1 rw, [8] MEM_CLKM_LDO_PMOS_PULLDN_CTRL rw, [7:5] RESERVED_2 rw, [4] MEM_PRIMARY_LDO_BYPASS rw, [3] RESERVED rw, [2] MEM_SEL_OV_FAST_CLK_SLICER_LDO_EN rw, [1] MEM_OV_FAST_CLK_SLICER_LDO_EN rw, [0] FAST_FCM_SLICER_LDO_EN rw
0x448 clk_slicer_en
  [15:3] RESERVED rw, [2] MEM_SEL_OV_FAST_CLK_SLICER_EN rw, [1] MEM_OV_FAST_CLK_SLICER_EN rw, [0] FAST_FSM_SLICER_EN rw
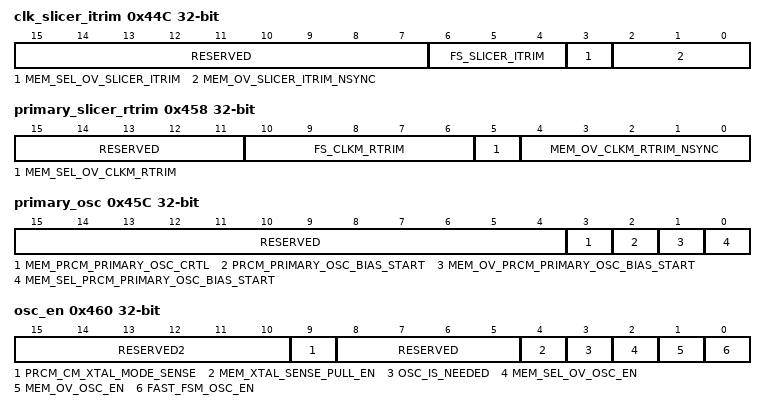
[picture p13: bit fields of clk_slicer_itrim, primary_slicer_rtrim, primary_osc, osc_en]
0x44C clk_slicer_itrim
  [15:7] RESERVED rw, [6:4] FS_SLICER_ITRIM rw, [3] MEM_SEL_OV_SLICER_ITRIM rw, [2:0] MEM_OV_SLICER_ITRIM_NSYNC rw
0x458 primary_slicer_rtrim
  [15:11] RESERVED rw, [10:6] FS_CLKM_RTRIM rw, [5] MEM_SEL_OV_CLKM_RTRIM rw, [4:0] MEM_OV_CLKM_RTRIM_NSYNC rw
0x45C primary_osc
  [15:4] RESERVED rw, [3] MEM_PRCM_PRIMARY_OSC_CRTL rw, [2] PRCM_PRIMARY_OSC_BIAS_START rw, [1] MEM_OV_PRCM_PRIMARY_OSC_BIAS_START rw, [0] MEM_SEL_PRCM_PRIMARY_OSC_BIAS_START rw
0x460 osc_en
  [15:10] RESERVED2 rw, [9] PRCM_CM_XTAL_MODE_SENSE rw, [8:5] RESERVED rw, [4] MEM_XTAL_SENSE_PULL_EN rw, [3] OSC_IS_NEEDED rw, [2] MEM_SEL_OV_OSC_EN rw, [1] MEM_OV_OSC_EN rw, [0] FAST_FSM_OSC_EN rw
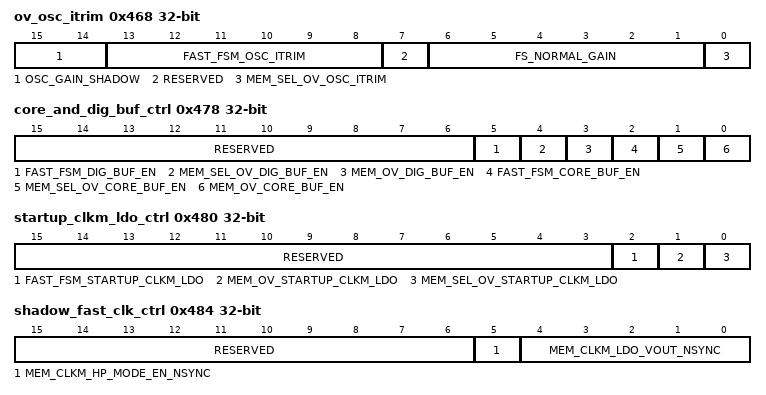
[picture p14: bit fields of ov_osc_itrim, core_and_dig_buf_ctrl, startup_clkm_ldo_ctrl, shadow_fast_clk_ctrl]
0x468 ov_osc_itrim
  [15:14] OSC_GAIN_SHADOW rw, [13:8] FAST_FSM_OSC_ITRIM rw, [7] RESERVED rw, [6:1] FS_NORMAL_GAIN rw, [0] MEM_SEL_OV_OSC_ITRIM rw
0x478 core_and_dig_buf_ctrl
  [15:6] RESERVED rw, [5] FAST_FSM_DIG_BUF_EN rw, [4] MEM_SEL_OV_DIG_BUF_EN rw, [3] MEM_OV_DIG_BUF_EN rw, [2] FAST_FSM_CORE_BUF_EN rw, [1] MEM_SEL_OV_CORE_BUF_EN rw, [0] MEM_OV_CORE_BUF_EN rw
0x480 startup_clkm_ldo_ctrl
  [15:3] RESERVED rw, [2] FAST_FSM_STARTUP_CLKM_LDO rw, [1] MEM_OV_STARTUP_CLKM_LDO rw, [0] MEM_SEL_OV_STARTUP_CLKM_LDO rw
0x484 shadow_fast_clk_ctrl
  [15:6] RESERVED rw, [5] MEM_CLKM_HP_MODE_EN_NSYNC rw, [4:0] MEM_CLKM_LDO_VOUT_NSYNC rw
0x488 slicer_bias_bypass_ctrl
  [15:3] RESERVED rw, [2:0] MEM_SLICER_BIAS_BYPASS rw
0x600 primary_en_tmux
  [15:3] RESERVED rw, [2:0] MEM_PRIMARY_EN_TMUX rw
0x608 primary_div_en
  [15:2] RESERVED rw, [1] MEM_OV_PRCM_PRIMARY_DIG_DIV4_EN rw, [0] MEM_OV_PRCM_PRIMARY_DIG_DIV2_EN rw
